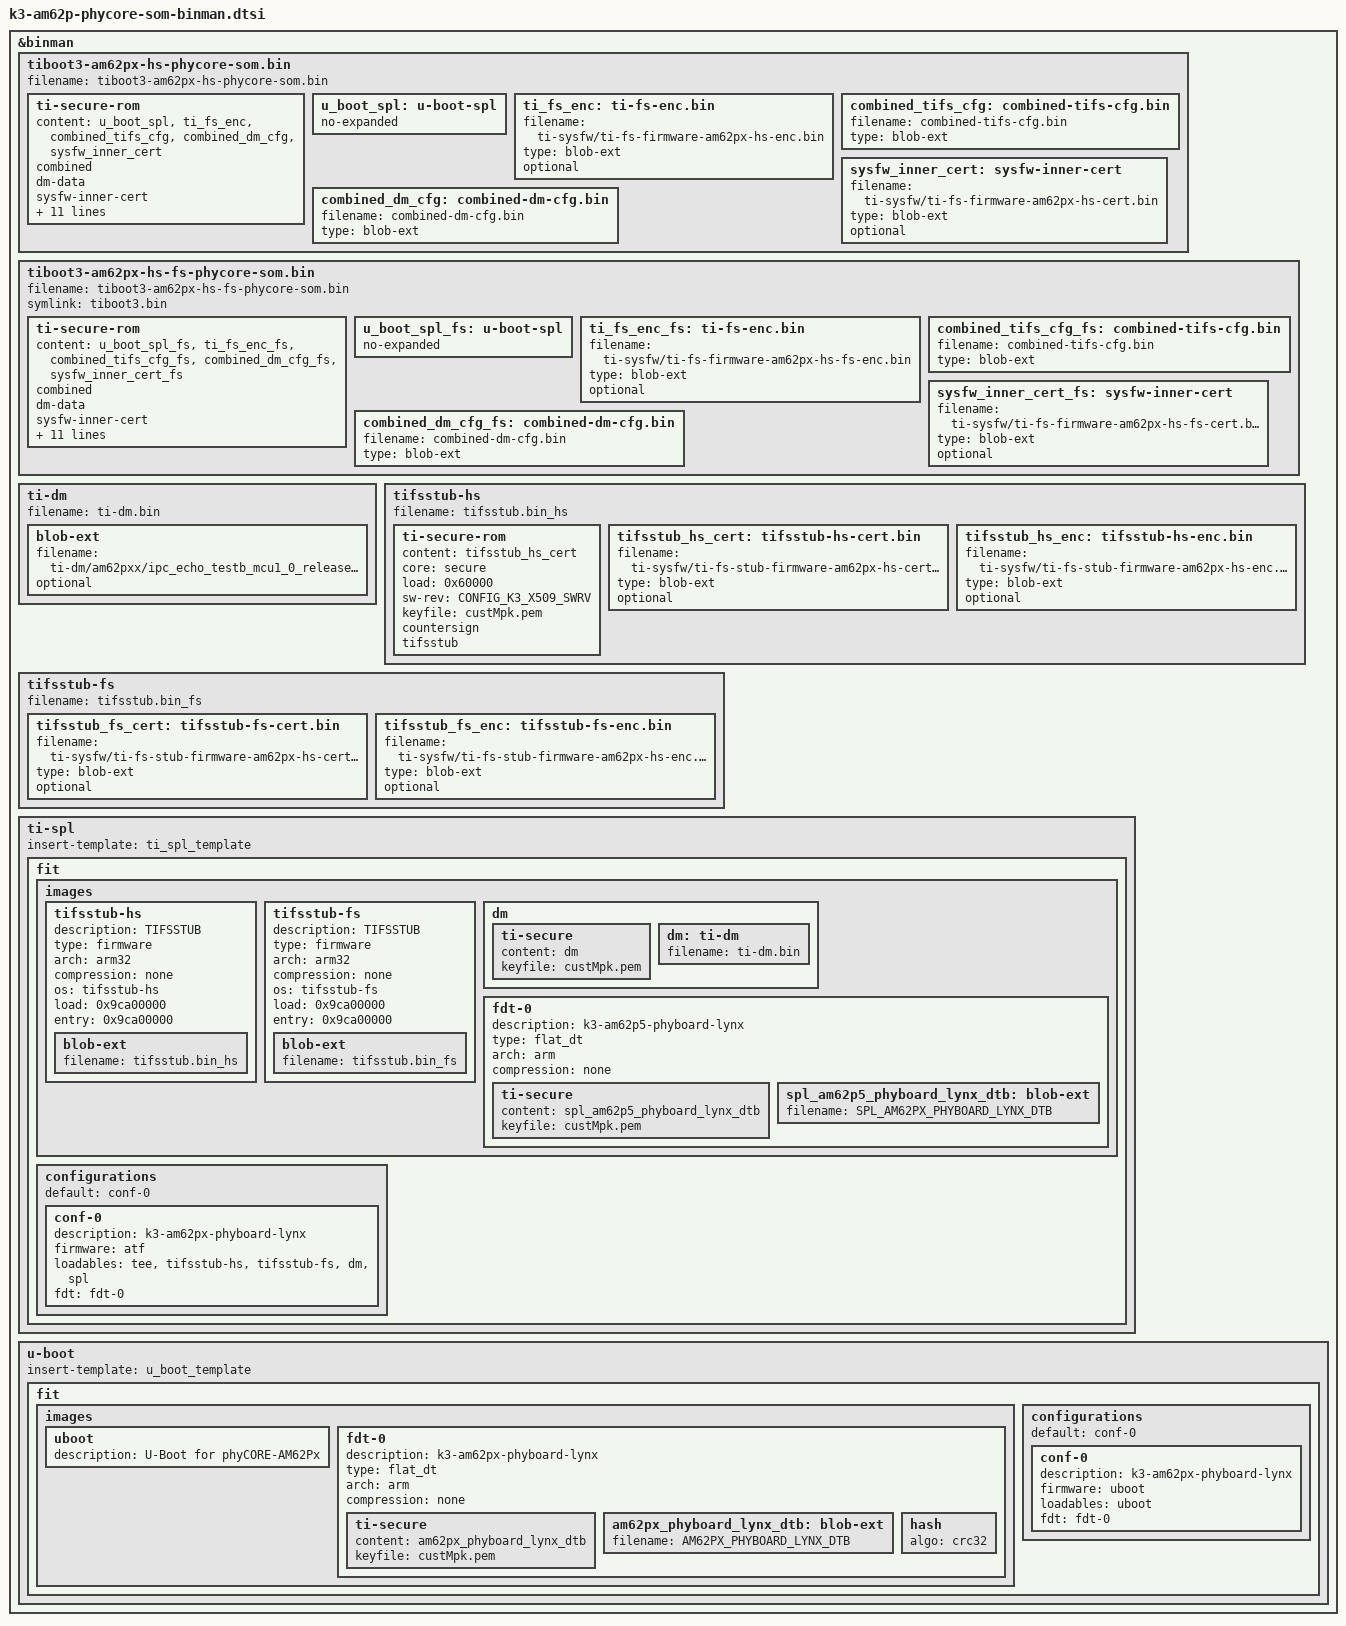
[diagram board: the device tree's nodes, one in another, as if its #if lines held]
// SPDX-License-Identifier: GPL-2.0-only OR MIT
/*
 * Copyright (C) 2025 PHYTEC America LLC - https://www.phytec.com/
 */

#include "k3-binman.dtsi"

#if IS_ENABLED(CONFIG_TARGET_PHYCORE_AM62PX_R5)

&binman {

	tiboot3-am62px-hs-phycore-som.bin {
		filename = "tiboot3-am62px-hs-phycore-som.bin";

		ti-secure-rom {
			content = <&u_boot_spl>, <&ti_fs_enc>, <&combined_tifs_cfg>,
				  <&combined_dm_cfg>, <&sysfw_inner_cert>;
			combined;
			dm-data;
			sysfw-inner-cert;
			keyfile = "custMpk.pem";
			sw-rev = <1>;
			content-sbl = <&u_boot_spl>;
			content-sysfw = <&ti_fs_enc>;
			content-sysfw-data = <&combined_tifs_cfg>;
			content-sysfw-inner-cert = <&sysfw_inner_cert>;
			content-dm-data = <&combined_dm_cfg>;
			load = <0x43c00000>;
			load-sysfw = <0x40000>;
			load-sysfw-data = <0x67000>;
			load-dm-data = <0x43c4a800>;
		};

		u_boot_spl: u-boot-spl {
			no-expanded;
		};

		ti_fs_enc: ti-fs-enc.bin {
			filename = "ti-sysfw/ti-fs-firmware-am62px-hs-enc.bin";
			type = "blob-ext";
			optional;
		};

		combined_tifs_cfg: combined-tifs-cfg.bin {
			filename = "combined-tifs-cfg.bin";
			type = "blob-ext";
		};

		sysfw_inner_cert: sysfw-inner-cert {
			filename = "ti-sysfw/ti-fs-firmware-am62px-hs-cert.bin";
			type = "blob-ext";
			optional;
		};

		combined_dm_cfg: combined-dm-cfg.bin {
			filename = "combined-dm-cfg.bin";
			type = "blob-ext";
		};
	};

	tiboot3-am62px-hs-fs-phycore-som.bin {
		filename = "tiboot3-am62px-hs-fs-phycore-som.bin";
		symlink = "tiboot3.bin";

		ti-secure-rom {
			content = <&u_boot_spl_fs>, <&ti_fs_enc_fs>, <&combined_tifs_cfg_fs>,
				  <&combined_dm_cfg_fs>, <&sysfw_inner_cert_fs>;
			combined;
			dm-data;
			sysfw-inner-cert;
			keyfile = "custMpk.pem";
			sw-rev = <1>;
			content-sbl = <&u_boot_spl_fs>;
			content-sysfw = <&ti_fs_enc_fs>;
			content-sysfw-data = <&combined_tifs_cfg_fs>;
			content-sysfw-inner-cert = <&sysfw_inner_cert_fs>;
			content-dm-data = <&combined_dm_cfg_fs>;
			load = <0x43c00000>;
			load-sysfw = <0x40000>;
			load-sysfw-data = <0x67000>;
			load-dm-data = <0x43c4a800>;
		};

		u_boot_spl_fs: u-boot-spl {
			no-expanded;
		};

		ti_fs_enc_fs: ti-fs-enc.bin {
			filename = "ti-sysfw/ti-fs-firmware-am62px-hs-fs-enc.bin";
			type = "blob-ext";
			optional;
		};

		combined_tifs_cfg_fs: combined-tifs-cfg.bin {
			filename = "combined-tifs-cfg.bin";
			type = "blob-ext";
		};

		sysfw_inner_cert_fs: sysfw-inner-cert {
			filename = "ti-sysfw/ti-fs-firmware-am62px-hs-fs-cert.bin";
			type = "blob-ext";
			optional;
		};

		combined_dm_cfg_fs: combined-dm-cfg.bin {
			filename = "combined-dm-cfg.bin";
			type = "blob-ext";
		};
	};
};

#endif /* CONFIG_TARGET_PHYCORE_AM62PX_R5 */

#if IS_ENABLED(CONFIG_TARGET_PHYCORE_AM62PX_A53)

#define SPL_AM62PX_PHYBOARD_LYNX_DTB "spl/dts/k3-am62p5-phyboard-lynx.dtb"
#define AM62PX_PHYBOARD_LYNX_DTB "u-boot.dtb"

&binman {
	ti-dm {
		filename = "ti-dm.bin";

		blob-ext {
			filename = "ti-dm/am62pxx/ipc_echo_testb_mcu1_0_release_strip.xer5f";
			optional;
		};
	};

	tifsstub-hs {
		filename = "tifsstub.bin_hs";
		ti-secure-rom {
			content = <&tifsstub_hs_cert>;
			core = "secure";
			load = <0x60000>;
			sw-rev = <CONFIG_K3_X509_SWRV>;
			keyfile = "custMpk.pem";
			countersign;
			tifsstub;
		};
		tifsstub_hs_cert: tifsstub-hs-cert.bin {
			filename = "ti-sysfw/ti-fs-stub-firmware-am62px-hs-cert.bin";
			type = "blob-ext";
			optional;
		};
		tifsstub_hs_enc: tifsstub-hs-enc.bin {
			filename = "ti-sysfw/ti-fs-stub-firmware-am62px-hs-enc.bin";
			type = "blob-ext";
			optional;
		};
	};

	tifsstub-fs {
		filename = "tifsstub.bin_fs";
		tifsstub_fs_cert: tifsstub-fs-cert.bin {
			filename = "ti-sysfw/ti-fs-stub-firmware-am62px-hs-cert.bin";
			type = "blob-ext";
			optional;
		};
		tifsstub_fs_enc: tifsstub-fs-enc.bin {
			filename = "ti-sysfw/ti-fs-stub-firmware-am62px-hs-enc.bin";
			type = "blob-ext";
			optional;
		};

	};

	ti-spl {
		insert-template = <&ti_spl_template>;

		fit {
			images {
				tifsstub-hs {
					description = "TIFSSTUB";
					type = "firmware";
					arch = "arm32";
					compression = "none";
					os = "tifsstub-hs";
					load = <0x9ca00000>;
					entry = <0x9ca00000>;
					blob-ext {
						filename = "tifsstub.bin_hs";
					};
				};

				tifsstub-fs {
					description = "TIFSSTUB";
					type = "firmware";
					arch = "arm32";
					compression = "none";
					os = "tifsstub-fs";
					load = <0x9ca00000>;
					entry = <0x9ca00000>;
					blob-ext {
						filename = "tifsstub.bin_fs";
					};
				};
				dm {
					ti-secure {
						content = <&dm>;
						keyfile = "custMpk.pem";
					};

					dm: ti-dm {
						filename = "ti-dm.bin";
					};
				};

				fdt-0 {
					description = "k3-am62p5-phyboard-lynx";
					type = "flat_dt";
					arch = "arm";
					compression = "none";

					ti-secure {
						content = <&spl_am62p5_phyboard_lynx_dtb>;
						keyfile = "custMpk.pem";
					};

					spl_am62p5_phyboard_lynx_dtb: blob-ext {
						filename = SPL_AM62PX_PHYBOARD_LYNX_DTB;
					};

				};

			};

			configurations {
				default = "conf-0";

				conf-0 {
					description = "k3-am62px-phyboard-lynx";
					firmware = "atf";
					loadables = "tee", "tifsstub-hs", "tifsstub-fs",
						    "dm", "spl";
					fdt = "fdt-0";
				};
			};
		};
	};
};

&binman {
	u-boot {
		insert-template = <&u_boot_template>;

		fit {
			images {
				uboot {
					description = "U-Boot for phyCORE-AM62Px";
				};

				fdt-0 {
					description = "k3-am62px-phyboard-lynx";
					type = "flat_dt";
					arch = "arm";
					compression = "none";

					ti-secure {
						content = <&am62px_phyboard_lynx_dtb>;
						keyfile = "custMpk.pem";
					};

					am62px_phyboard_lynx_dtb: blob-ext {
						filename = AM62PX_PHYBOARD_LYNX_DTB;
					};

					hash {
						algo = "crc32";
					};
				};
			};

			configurations {
				default = "conf-0";

				conf-0 {
					description = "k3-am62px-phyboard-lynx";
					firmware = "uboot";
					loadables = "uboot";
					fdt = "fdt-0";
				};

			};
		};
	};
};

#endif /* CONFIG_TARGET_PHYCORE_AM62PX_A53 */
